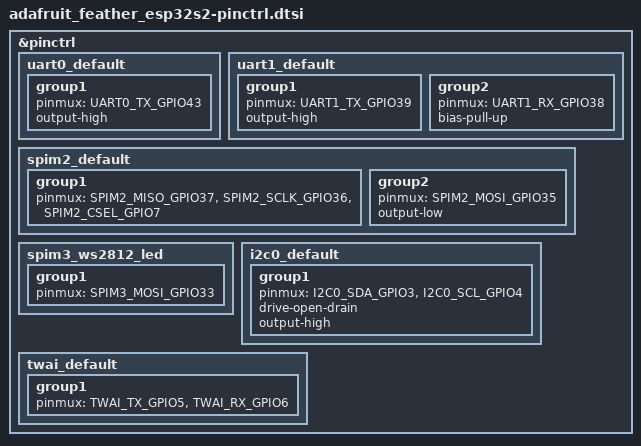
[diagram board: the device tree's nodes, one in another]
/*
 * Copyright (c) 2025 Philipp Steiner <philipp.steiner@gmail.com>.
 *
 * SPDX-License-Identifier: Apache-2.0
 */

#include <zephyr/dt-bindings/pinctrl/esp-pinctrl-common.h>
#include <dt-bindings/pinctrl/esp32s2-pinctrl.h>
#include <zephyr/dt-bindings/pinctrl/esp32s2-gpio-sigmap.h>

&pinctrl {
	/*  Debug TX (DBG) - This is the hardware UART debug pin */
	uart0_default: uart0_default {
		group1 {
			pinmux = <UART0_TX_GPIO43>;
			output-high;
		};
	};

	uart1_default: uart1_default {
		group1 {
			pinmux = <UART1_TX_GPIO39>;
			output-high;
		};

		group2 {
			pinmux = <UART1_RX_GPIO38>;
			bias-pull-up;
		};
	};

	spim2_default: spim2_default {
		group1 {
			pinmux = <SPIM2_MISO_GPIO37>,
				 <SPIM2_SCLK_GPIO36>,
				 <SPIM2_CSEL_GPIO7>;
		};

		group2 {
			pinmux = <SPIM2_MOSI_GPIO35>;
			output-low;
		};
	};

	spim3_ws2812_led: spim3_ws2812_led {
		group1 {
			pinmux = <SPIM3_MOSI_GPIO33>;
		};
	};

	i2c0_default: i2c0_default {
		group1 {
			pinmux = <I2C0_SDA_GPIO3>,
				 <I2C0_SCL_GPIO4>;
			drive-open-drain;
			output-high;
		};
	};

	twai_default: twai_default {
		group1 {
			pinmux = <TWAI_TX_GPIO5>,
				 <TWAI_RX_GPIO6>;
		};
	};
};
